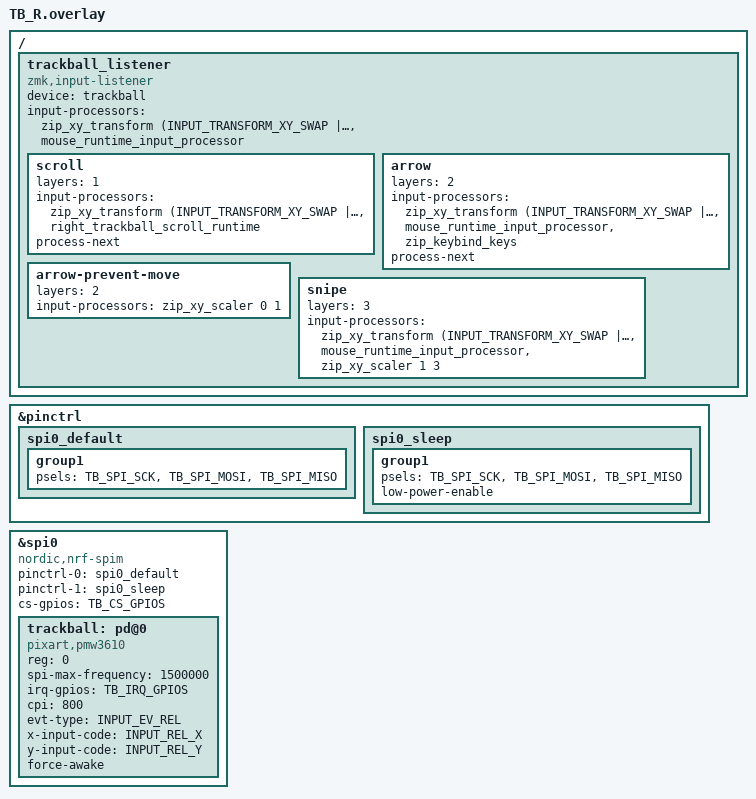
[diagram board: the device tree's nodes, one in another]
#include <input/processors.dtsi>
#include <dt-bindings/zmk/input_transform.h>
#include <zephyr/dt-bindings/input/input-event-codes.h>
#include <input/processors/runtime-input-processor.dtsi>

/ {
    trackball_listener: trackball_listener {
        compatible = "zmk,input-listener";
        status = "okay";
        device = <&trackball>;
        input-processors = <&zip_xy_transform (INPUT_TRANSFORM_XY_SWAP | INPUT_TRANSFORM_X_INVERT)>,
                           <&mouse_runtime_input_processor>;

        scroll {
            layers = <1>;
            input-processors = <&zip_xy_transform (INPUT_TRANSFORM_XY_SWAP | INPUT_TRANSFORM_X_INVERT)>,
                               <&right_trackball_scroll_runtime>;
            process-next;
        };

        arrow {
            layers = <2>;
            input-processors = <&zip_xy_transform (INPUT_TRANSFORM_XY_SWAP | INPUT_TRANSFORM_X_INVERT)>,
                               <&mouse_runtime_input_processor>,
                               <&zip_keybind_keys>;
            process-next;
        };

        arrow-prevent-move {
            layers = <2>;
            input-processors = <&zip_xy_scaler 0 1>;
        };

        snipe {
            layers = <3>;
            input-processors = <&zip_xy_transform (INPUT_TRANSFORM_XY_SWAP | INPUT_TRANSFORM_X_INVERT)>,
                               <&mouse_runtime_input_processor>,
                               <&zip_xy_scaler 1 3>;
        };
    };
};

&pinctrl {
    spi0_default: spi0_default {
        group1 {
            psels = <TB_SPI_SCK>,
                    <TB_SPI_MOSI>,
                    <TB_SPI_MISO>;
        };
    };

    spi0_sleep: spi0_sleep {
        group1 {
            psels = <TB_SPI_SCK>,
                    <TB_SPI_MOSI>,
                    <TB_SPI_MISO>;
            low-power-enable;
        };
    };
};

&spi0 {
    status = "okay";
    compatible = "nordic,nrf-spim";
    pinctrl-0 = <&spi0_default>;
    pinctrl-1 = <&spi0_sleep>;
    pinctrl-names = "default", "sleep";
    cs-gpios = TB_CS_GPIOS;

    trackball: pd@0 {
        status = "okay";
        compatible = "pixart,pmw3610";
        reg = <0>;
        spi-max-frequency = <1500000>;
        irq-gpios = TB_IRQ_GPIOS;
        cpi = <800>;
        evt-type = <INPUT_EV_REL>;
        x-input-code = <INPUT_REL_X>;
        y-input-code = <INPUT_REL_Y>;
        force-awake;
    };
};
